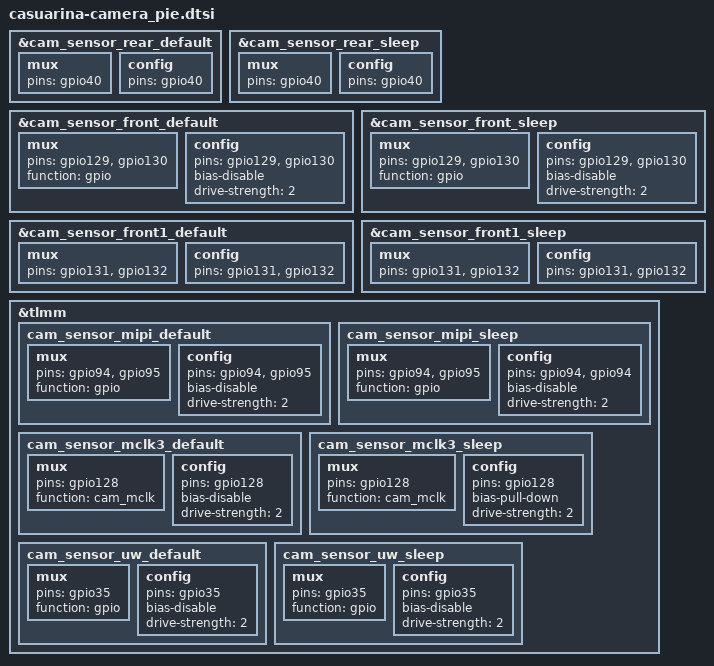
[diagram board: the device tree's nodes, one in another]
&cam_sensor_rear_default {
	mux {
		pins = "gpio40";
	};

	config {
		pins = "gpio40";
	};
};

&cam_sensor_rear_sleep {
	mux {
		pins = "gpio40";
	};

	config {
		pins = "gpio40";
	};
};

&cam_sensor_front_default {
	mux {
		pins = "gpio129","gpio130";
		function = "gpio";
	};

	config {
		pins = "gpio129","gpio130";
		bias-disable; /* No PULL */
		drive-strength = <2>; /* 2 MA */
	};
};

&cam_sensor_front_sleep {
	mux {
		pins = "gpio129","gpio130";
		function = "gpio";
	};

	config {
		pins = "gpio129","gpio130";
		bias-disable; /* No PULL */
		drive-strength = <2>; /* 2 MA */
	};
};

&cam_sensor_front1_default {
	mux {
		pins = "gpio131", "gpio132";
	};

	config {
		pins = "gpio131", "gpio132";
	};
};

&cam_sensor_front1_sleep {
	mux {
		pins = "gpio131", "gpio132";
	};

	config {
		pins = "gpio131", "gpio132";
	};
};

&tlmm {
    cam_sensor_mipi_default: cam_sensor_mipi_default {
		/* POW, SEL */
        mux {
			pins = "gpio94","gpio95";
			function = "gpio";
        };

        config {
			pins = "gpio94","gpio95";
			bias-disable; /* No PULL */
			drive-strength = <2>; /* 2 MA */
        };
    };

    cam_sensor_mipi_sleep: cam_sensor_mipi_sleep {
		/* POW, SEL */
        mux {
			pins = "gpio94","gpio95";
			function = "gpio";
        };

        config {
			pins = "gpio94","gpio94";
			bias-disable; /* No PULL */
			drive-strength = <2>; /* 2 MA */
        };
    };

	cam_sensor_mclk3_default: cam_sensor_mclk3_default {
		mux {
			/* CLK, DATA */
			pins = "gpio128";
			function = "cam_mclk";
		};

		config {
			pins = "gpio128";
			bias-disable; /* No PULL */
			drive-strength = <2>; /* 2 MA */
		};
	};

	cam_sensor_mclk3_sleep: cam_sensor_mclk3_sleep {
		/* MCLK3 */
		mux {
			/* CLK, DATA */
			pins = "gpio128";
			function = "cam_mclk";
		};

		config {
			pins = "gpio128";
			bias-pull-down; /* PULL DOWN */
			drive-strength = <2>; /* 2 MA */
		};
	};

	cam_sensor_uw_default: cam_sensor_uw_default {
		/* RESET */
		mux {
			pins = "gpio35";
			function = "gpio";
		};

		config {
			pins = "gpio35";
			bias-disable; /* No PULL */
			drive-strength = <2>; /* 2 MA */
		};
	};

	cam_sensor_uw_sleep: cam_sensor_uw_sleep {
		/* RESET */
		mux {
			pins = "gpio35";
			function = "gpio";
		};

		config {
			pins = "gpio35";
			bias-disable; /* No PULL */
			drive-strength = <2>; /* 2 MA */
		};
	};
};
